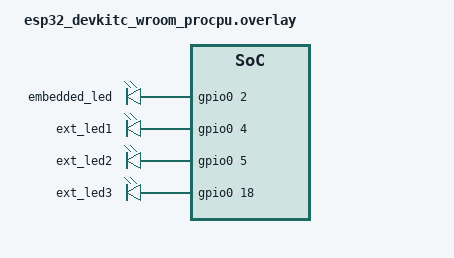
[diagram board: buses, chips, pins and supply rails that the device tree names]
/ {
    led {
        compatible = "gpio-leds";
        embedded_led: embedded_led {
            gpios = <&gpio0 2 GPIO_ACTIVE_HIGH>;
        };
        ext_led1: ext_led1 {
            gpios = <&gpio0 4 GPIO_ACTIVE_HIGH>;
        };
        ext_led2: ext_led2 {
            gpios = <&gpio0 5 GPIO_ACTIVE_HIGH>;
        };
        ext_led3: ext_led3 {
            gpios = <&gpio0 18 GPIO_ACTIVE_HIGH>;
        };
    };
};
